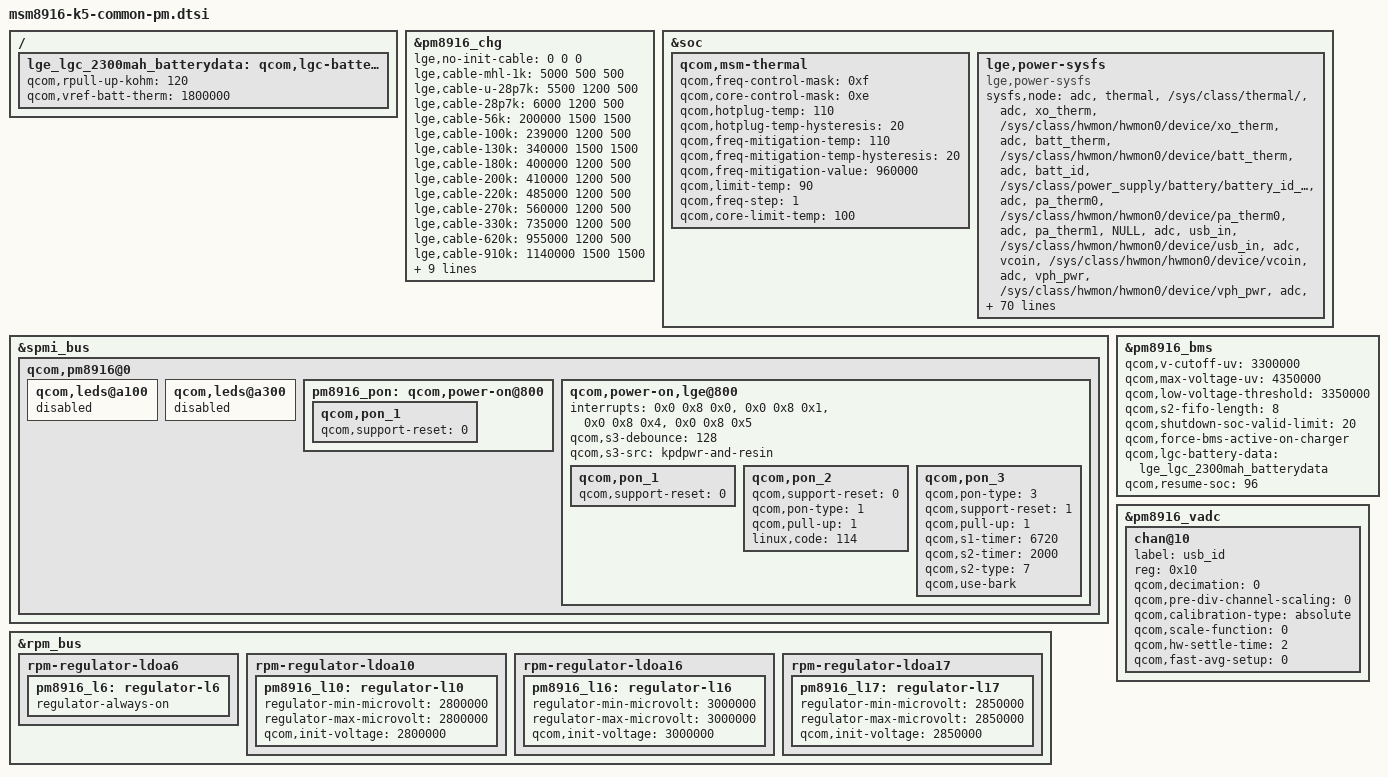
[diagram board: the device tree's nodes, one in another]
/* Copyright (c) 2012, Code Aurora Forum. All rights reserved.
 *
 * This program is free software; you can redistribute it and/or modify
* it under the terms of the GNU General Public License version 2 and
* only version 2 as published by the Free Software Foundation.
*
* This program is distributed in the hope that it will be useful,
* but WITHOUT ANY WARRANTY; without even the implied warranty of
* MERCHANTABILITY or FITNESS FOR A PARTICULAR PURPOSE.  See the
* GNU General Public License for more details.
*/

&pm8916_chg {
	status = "ok";

	lge,no-init-cable = <0 0 0>;
	lge,cable-mhl-1k = <5000 500 500>;
	lge,cable-u-28p7k = <5500 1200 500>;
	lge,cable-28p7k = <6000 1200 500>;
	lge,cable-56k = <200000 1500 1500>;
	lge,cable-100k = <239000 1200 500>;
	lge,cable-130k = <340000 1500 1500>;
	lge,cable-180k = <400000 1200 500>;
	lge,cable-200k = <410000 1200 500>;
	lge,cable-220k = <485000 1200 500>;
	lge,cable-270k = <560000 1200 500>;
	lge,cable-330k = <735000 1200 500>;
	lge,cable-620k = <955000 1200 500>;
	lge,cable-910k = <1140000 1500 1500>;
	lge,cable-none = <1900000 810  500>;

	qcom,vddmax-mv = <4350>;
	qcom,vddsafe-mv = <4380>;
	qcom,vinmin-mv = <4450>;
	qcom,tchg-mins = <480>;
	qcom,btc-disabled;
	qcom,resume-soc = <96>;
	qcom,disable-vbatdet-based-recharge;

	/* Pins config setting */
	pinctrl-names = "sleep";
	pinctrl-1 = <&nc_sleep>;
};

&soc {
	qcom,msm-thermal {
		qcom,freq-control-mask = <0xf>;
		qcom,core-control-mask = <0xe>;
		qcom,hotplug-temp = <110>;
		qcom,hotplug-temp-hysteresis = <20>;
		qcom,freq-mitigation-temp = <110>;
		qcom,freq-mitigation-temp-hysteresis = <20>;
		qcom,freq-mitigation-value = <960000>;
		qcom,limit-temp = <90>;
		qcom,freq-step = <1>;
		qcom,core-limit-temp = <100>;
		};
};

&spmi_bus {
	qcom,pm8916@0 {
		qcom,leds@a100 {
			status = "disabled";
		};

		qcom,leds@a300 {
			status = "disabled";
		};
		pm8916_pon: qcom,power-on@800 {
			qcom,pon_1 {
				qcom,support-reset = <0>;
			};
		};
		qcom,power-on,lge@800{
			interrupts = <0x0 0x8 0x0>,
				     <0x0 0x8 0x1>,
				     <0x0 0x8 0x4>,
				     <0x0 0x8 0x5>;
			interrupt-names = "kpdpwr", "resin",
				  "resin-bark", "kpdpwr-resin-bark";
			qcom,s3-debounce = <128>;
			qcom,s3-src = "kpdpwr-and-resin";

			qcom,pon_1 {
				status = "ok";
				qcom,support-reset = <0>;
			};

			qcom,pon_2 { /* RESIN_N reset   */
				status = "ok";
				qcom,support-reset = <0>;
				qcom,pon-type = <1>;
				qcom,pull-up = <1>;
				linux,code = <114>;
			};

			qcom,pon_3 { /* KPD_PWR_N AND RESIN_N reset */
				status = "ok";
				qcom,pon-type = <3>;
				qcom,support-reset = <1>;
				qcom,pull-up = <1>;
				qcom,s1-timer = <6720>;
				qcom,s2-timer = <2000>;
				qcom,s2-type = <7>;
				qcom,use-bark;
			};
		};
	};
};

/ {
	lge_lgc_2300mah_batterydata: qcom,lgc-battery-data {
		qcom,rpull-up-kohm = <120>;
		qcom,vref-batt-therm = <1800000>;

		#include "../msm8916-lge-common/batterydata_LGE_lgc_BLT9_2300mAh.dtsi"
	};
};

&pm8916_bms {
	status = "ok";
	qcom,v-cutoff-uv = <3300000>;
	qcom,max-voltage-uv = <4350000>;
	qcom,low-voltage-threshold = <3350000>;
	qcom,s2-fifo-length = <8>;
	qcom,shutdown-soc-valid-limit = <20>;
	qcom,force-bms-active-on-charger;
	qcom,lgc-battery-data = <&lge_lgc_2300mah_batterydata>;
	qcom,resume-soc = <96>;
};

&pm8916_vadc {
	chan@10 {
		label = "usb_id";
		reg = <0x10>;
		qcom,decimation = <0>;
		qcom,pre-div-channel-scaling = <0>;
		qcom,calibration-type = "absolute";
		qcom,scale-function = <0>;
		qcom,hw-settle-time = <2>;
		qcom,fast-avg-setup = <0>;
	};
};

&rpm_bus {
	rpm-regulator-ldoa6 {
		status = "okay";
		pm8916_l6: regulator-l6 {
			regulator-always-on;
			status = "okay";
		};
	};

	rpm-regulator-ldoa10 {
		status = "okay";
		pm8916_l10: regulator-l10 {
			regulator-min-microvolt = <2800000>;
			regulator-max-microvolt = <2800000>;
			qcom,init-voltage = <2800000>;
			//regulator-always-on;
			status = "okay";
		};
	};

	rpm-regulator-ldoa16 {
		status = "okay";
		pm8916_l16: regulator-l16 {
			regulator-min-microvolt = <3000000>;
			regulator-max-microvolt = <3000000>;
			qcom,init-voltage = <3000000>;
			status = "okay";
		};
	};

	rpm-regulator-ldoa17 {
		status = "okay";
		pm8916_l17: regulator-l17 {
			regulator-min-microvolt = <2850000>;
			regulator-max-microvolt = <2850000>;
			qcom,init-voltage = <2850000>;
			//regulator-always-on;
			status = "okay";
		};
	};
};

&soc {
	lge,power-sysfs {
		compatible = "lge,power-sysfs";

		sysfs,node =
			/* group , user_node,  kernel node */
			/* ADC/MPP */
			"adc", "thermal", "/sys/class/thermal/",
			"adc", "xo_therm", "/sys/class/hwmon/hwmon0/device/xo_therm",
			"adc", "batt_therm", "/sys/class/hwmon/hwmon0/device/batt_therm",
			"adc", "batt_id", "/sys/class/power_supply/battery/battery_id_checker",
			"adc", "pa_therm0", "/sys/class/hwmon/hwmon0/device/pa_therm0",
			"adc", "pa_therm1", "NULL",
			"adc", "usb_in", "/sys/class/hwmon/hwmon0/device/usb_in",
			"adc", "vcoin", "/sys/class/hwmon/hwmon0/device/vcoin",
			"adc", "vph_pwr", "/sys/class/hwmon/hwmon0/device/vph_pwr",
			"adc", "usb_id", "/sys/class/hwmon/hwmon0/device/usb_id",
			/* Battery */
			"battery", "capacity", "/sys/class/power_supply/battery/capacity",
			"battery", "health", "/sys/class/power_supply/battery/health",
			"battery", "present", "/sys/class/power_supply/battery/present",
			"battery", "pseudo_batt", "/sys/class/power_supply/battery/pseudo_batt",
			"battery", "status", "/sys/class/power_supply/battery/status",
			"battery", "temp", "/sys/class/power_supply/battery/temp",
			"battery", "valid_batt_id", "/sys/class/power_supply/battery/valid_batt_id",
			"battery", "voltage_now", "/sys/class/power_supply/battery/voltage_now",
			/* Charger */
			"charger", "ac_online", "NULL",
			"charger", "usb_online", "/sys/class/power_supply/usb/online",
			"charger", "present", "/sys/class/power_supply/usb/present",
			"charger", "wlc_online", "NULL",
			"charger", "type", "/sys/class/power_supply/usb/type",
			"charger", "time_out", "NULL",
			"charger", "charging_enabled", "/sys/class/power_supply/battery/charging_enabled",
			"charger", "ibat_current", "/sys/class/power_supply/battery/current_now",
			"charger", "ichg_current", "/sys/class/power_supply/usb/current_max",
			"charger", "iusb_control", "NULL",
			"charger", "thermal_mitigation", "/sys/module/bq24262_charger/parameters/bq24262_thermal_mitigation",
			"charger", "wlc_thermal_mitigation", "NULL",
			"charger", "usb_parallel_chg_status", "NULL",
			"charger", "usb_parallel_charging_enabled", "NULL",
			/* LCD Backlight */
			"lcd", "brightness", "/sys/class/leds/lcd-backlight/brightness",
			"lcd", "max_brightness", "/sys/class/leds/lcd-backlight/max_brightness",
			/* LCD Backlight EX */
			"lcd_ex", "brightness", "/sys/class/leds/lcd-backlight-ex/brightness",
			"lcd_ex", "max_brightness", "/sys/class/leds/lcd-backlight-ex/max_brightness",
			/* KEY LED */
			"key_led", "red_brightness", "/sys/class/leds/red/brightness",
			"key_led", "green_brightness", "NULL",
			"key_led", "blue_brightness", "NULL",
			/* CPU */
			"cpu", "cpu_idle_modes", "NULL",
			/* GPU */
			"gpu", "busy", "/sys/class/kgsl/kgsl-3d0/gpubusy",
			/* PLATFORM */
			"platform", "speed_bin", "NULL",
			"platform", "pvs_bin", "NULL",
			"platform", "power_state", "/sys/power/autosleep",
			"platform", "poweron_alarm", "/sys/module/qpnp_rtc/parameters/poweron_alarm",
			"platform", "pcb_rev", "/sys/class/power_supply/battery/hw_rev",
			/* testmode */
			"testmode", "charge", "/sys/class/power_supply/battery/device/at_charge",
			"testmode", "chcomp", "/sys/class/power_supply/battery/device/at_chcomp1",
			"testmode", "chgmodeoff", "/sys/class/power_supply/battery/charging_enabled",
			"testmode", "fuelrst", "/sys/bus/i2c/devices/1-0036/fuelrst",
			"testmode", "rtc_time", "/dev/rtc0",
			"testmode", "pmrst", "NULL",
			"testmode", "battexit", "/sys/class/power_supply/battery/present",
			"testmode", "hw_rev", "/sys/class/power_supply/battery/hw_rev"
			;
	};
};
